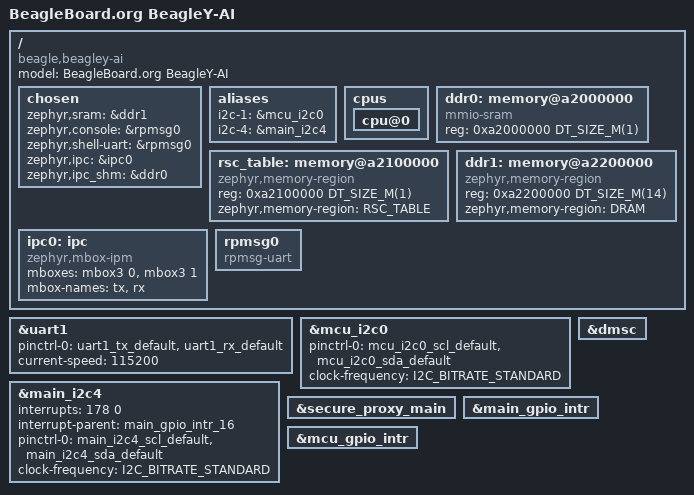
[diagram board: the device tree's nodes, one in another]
/*
 * Copyright (c) 2024 Texas Instruments Incorporated
 *	Andrew Davis <afd@ti.com>
 *
 * SPDX-License-Identifier: Apache-2.0
 */

/dts-v1/;

#include <ti/j722s_main_r5.dtsi>
#include "beagley_ai_j722s_r5f0_0-pinctrl.dtsi"
#include <zephyr/dt-bindings/i2c/i2c.h>

/ {
	model = "BeagleBoard.org BeagleY-AI";
	compatible = "beagle,beagley-ai";

	chosen {
		zephyr,sram = &ddr1;
		zephyr,console = &rpmsg0;
		zephyr,shell-uart = &rpmsg0;
		zephyr,ipc = &ipc0;
		zephyr,ipc_shm = &ddr0;
	};

	aliases {
		/*
		 * HAT i2c1 (GPIO2/3) = MCU_I2C0 — usable from Main R5 via VIM 197
		 * (see j722s_mcu.dtsi). HAT i2c4 (GPIO22/25) = MAIN_I2C4 via
		 * MAIN GPIOMUX INTROUTER input 178 (not direct VIM 239).
		 */
		i2c-1 = &mcu_i2c0;
		i2c-4 = &main_i2c4;
	};

	cpus {
		cpu@0 {
			status = "okay";
		};
	};

	ddr0: memory@a2000000 {
		compatible = "mmio-sram";
		reg = <0xa2000000 DT_SIZE_M(1)>;
	};

	rsc_table: memory@a2100000 {
		compatible = "zephyr,memory-region", "mmio-sram";
		reg = <0xa2100000 DT_SIZE_M(1)>;
		zephyr,memory-region = "RSC_TABLE";
	};

	ddr1: memory@a2200000 {
		compatible = "zephyr,memory-region", "mmio-sram";
		reg = <0xa2200000 DT_SIZE_M(14)>;
		zephyr,memory-region = "DRAM";
	};

	ipc0: ipc {
		compatible = "zephyr,mbox-ipm";
		mboxes = <&mbox3 0>, <&mbox3 1>;
		mbox-names = "tx", "rx";
	};

	rpmsg0: rpmsg0 {
		compatible = "rpmsg-uart";
		status = "okay";
	};
};

&uart1 {
	status = "okay";
	pinctrl-0 = <&uart1_tx_default &uart1_rx_default>;
	pinctrl-names = "default";
	current-speed = <115200>;
};

/*
 * HAT i2c1: MCU_I2C0 on Main R5 VIM 197 (j722s_mcu.dtsi is included by
 * j722s_main_r5.dtsi). Keep MCU R5 offline so it does not contend for the IP.
 */
&mcu_i2c0 {
	status = "okay";
	pinctrl-0 = <&mcu_i2c0_scl_default &mcu_i2c0_sda_default>;
	pinctrl-names = "default";
	clock-frequency = <I2C_BITRATE_STANDARD>;
};

/*
 * HAT i2c4 controller: I2C4_POINTRPEND is MAIN GPIOMUX IR input 178.
 * Board picks IR output 16 → VIM 104 via ti,sci-intr-out child.
 */
&main_i2c4 {
	status = "okay";
	interrupts = <178 0>;
	interrupt-parent = <&main_gpio_intr_16>;
	pinctrl-0 = <&main_i2c4_scl_default &main_i2c4_sda_default>;
	pinctrl-names = "default";
	clock-frequency = <I2C_BITRATE_STANDARD>;
};

&secure_proxy_main {
	status = "okay";
};

&dmsc {
	status = "okay";
};

&main_gpio_intr {
	status = "okay";
};

&mcu_gpio_intr {
	status = "okay";
};
